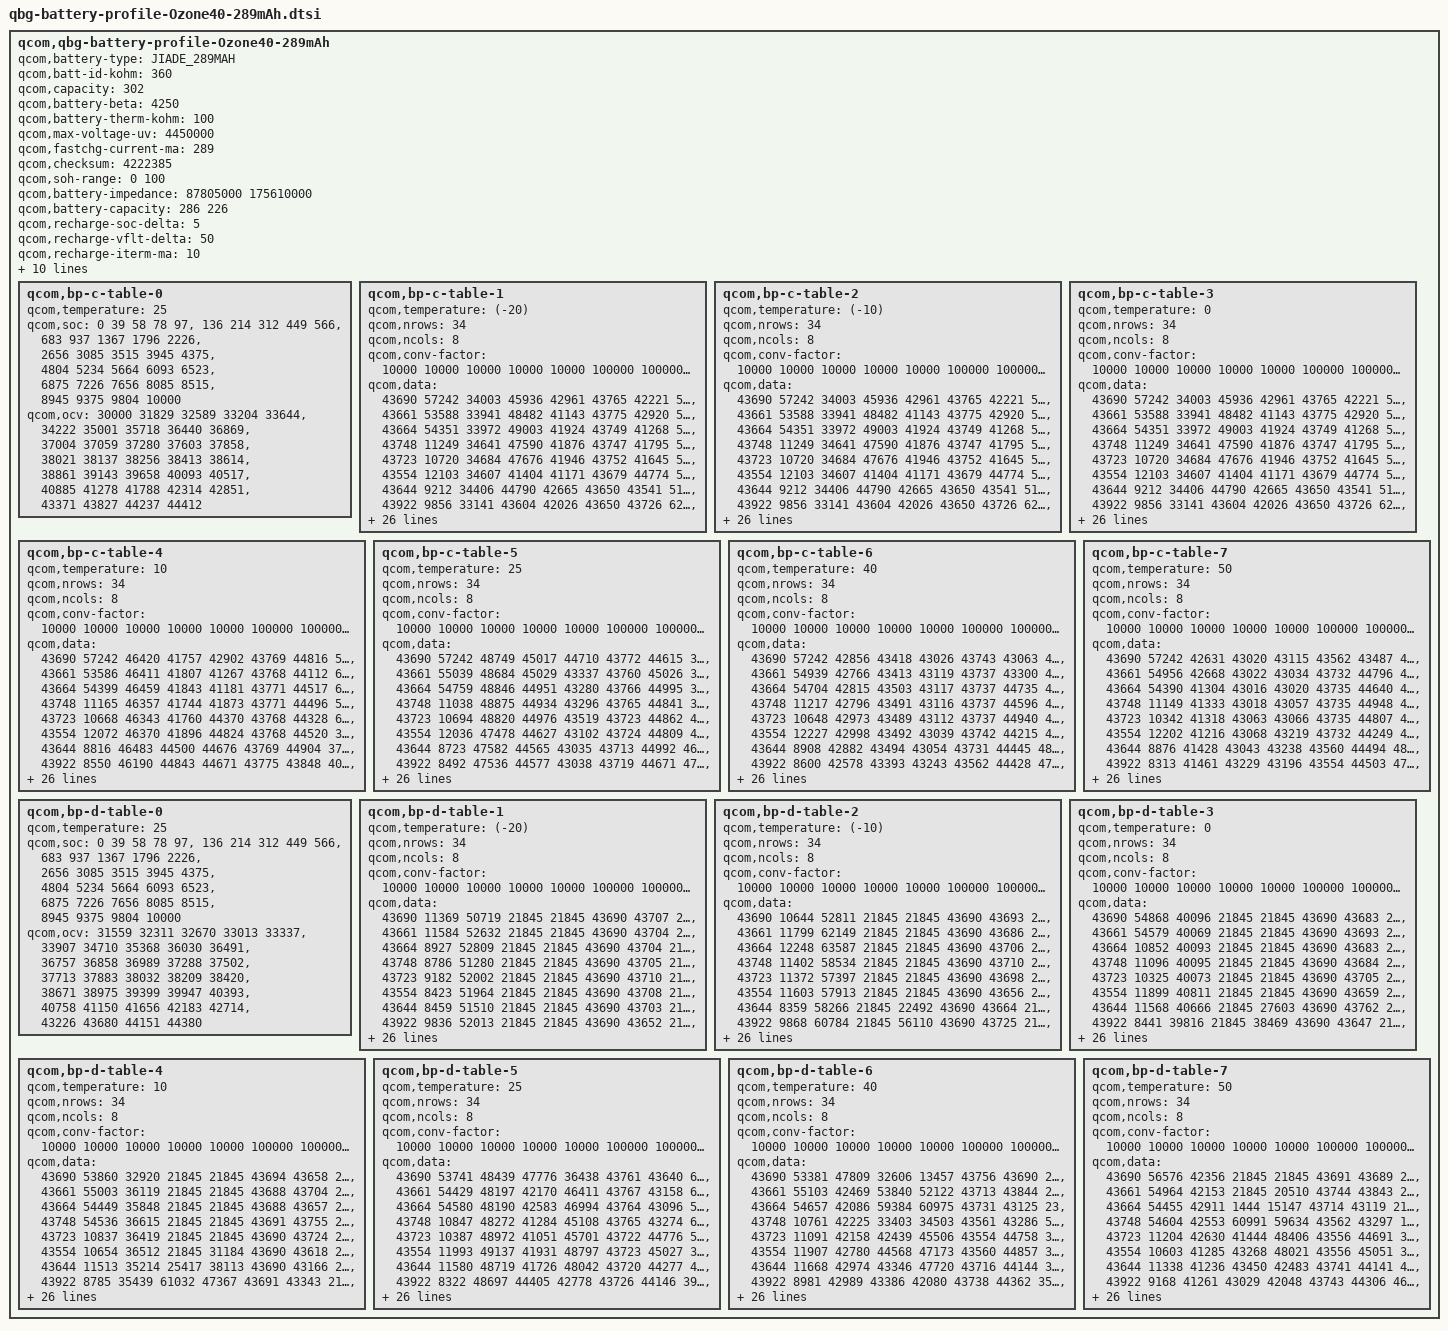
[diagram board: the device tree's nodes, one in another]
qcom,qbg-battery-profile-Ozone40-289mAh {
	qcom,battery-type = "JIADE_289MAH";
	qcom,batt-id-kohm = <360>;
	qcom,capacity = <302>;
	qcom,battery-beta = <4250>;
	qcom,battery-therm-kohm = <100>;
	qcom,max-voltage-uv = <4450000>;
	qcom,fastchg-current-ma = <289>;
	qcom,checksum = <4222385>; /*@5, 0.005V, 4% */
	qcom,soh-range = <0 100>;
	/* Nominal_Impedance in 10nohm @ SOC 50% 25C* 0:fresh cell, 1: aged cell */
	qcom,battery-impedance = <87805000 175610000>;
	/* Nominal_Capacity in mAh. 0: fresh cell, 1:aged cell */
	qcom,battery-capacity = <286 226>;
	/* SOC delta (in percent) dropped from EOC SOC to enable recharge */
	qcom,recharge-soc-delta =<5>;
	/* vfloat delta (in mV) dropped from regular vfloat in recharge */
	qcom,recharge-vflt-delta =<50>;
	/* Termination current (in mA) in recharge */
	qcom,recharge-iterm-ma = <10>;

	qcom,jeita-fcc-ranges = <0 150 58000
				151 435 289000
				436 445 260000
				446 450 58000>;

	qcom,jeita-fv-ranges = <0 150 4300000
				151 435 4450000
				436 445 4450000
				446 450 4350000>;

	/* COOL = 15 DegC, WARM = 45 DegC */
	qcom,jeita-soft-thresholds = <0x27c1 0x128c>;
	/* COLD = 0 DegC, HOT = 45.1 DegC */
	qcom,jeita-hard-thresholds = <0x3257 0x127e>;
	/* COOL = 18 DegC, WARM = 44 DegC*/
	qcom,jeita-soft-hys-thresholds = <0x256e 0x131c>;
	qcom,step-jeita-hysteresis = <5 5>;
	qcom,jeita-soft-fcc-ua = <96000 289000>;
	qcom,jeita-soft-fv-uv = <4300000 4300000>;

	qcom,bp-c-table-0 {
		qcom,temperature = <25>;
		qcom,soc = <    0    39    58    78    97>,
			<  136   214   312   449   566>,
			<  683   937  1367  1796  2226>,
			< 2656  3085  3515  3945  4375>,
			< 4804  5234  5664  6093  6523>,
			< 6875  7226  7656  8085  8515>,
			< 8945  9375  9804 10000>;
		qcom,ocv = <30000 31829 32589 33204 33644>,
			<34222 35001 35718 36440 36869>,
			<37004 37059 37280 37603 37858>,
			<38021 38137 38256 38413 38614>,
			<38861 39143 39658 40093 40517>,
			<40885 41278 41788 42314 42851>,
			<43371 43827 44237 44412>;
	};
	qcom,bp-c-table-1 {
		qcom,temperature = <(-20)>;
		qcom,nrows = <34>;
		qcom,ncols = <8>;
		qcom,conv-factor = <10000 10000 10000 10000 10000 100000 100000 10000>;
		qcom,data = <43690 57242 34003 45936 42961 43765 42221 54386>,
			<43661 53588 33941 48482 41143 43775 42920 54227>,
			<43664 54351 33972 49003 41924 43749 41268 56556>,
			<43748 11249 34641 47590 41876 43747 41795 55361>,
			<43723 10720 34684 47676 41946 43752 41645 50477>,
			<43554 12103 34607 41404 41171 43679 44774 50052>,
			<43644  9212 34406 44790 42665 43650 43541 51988>,
			<43922  9856 33141 43604 42026 43650 43726 62584>,
			<43883  9301 33066 43565 42160 43664 43724 61736>,
			<43164 15062 33073 43733 42763 43668 43727 62334>,
			<43009 14925 33233 43534 42875 43668 43725 61973>,
			<43267 15261 33115 41943 44247 43770 43061 62463>,
			<45053 14466 33169 42923 44407 43774 44995 61753>,
			<44462 14808 32780 42859 41097 43763 44898 63117>,
			<41496 16094 32980 42239 41249 43760 44896 63183>,
			<41162 16319 32991 42058 42532 43760 44844 62985>,
			<42663 16325 32964 42488 42951 43763 44996 63004>,
			<42769 16248 33536 42242 42821 43762 45027 63083>,
			<42435 15587 33016 47805 42011 43773 45031 63377>,
			<48061 15478 33758 47640 42298 43772 44800 62626>,
			<47214 15642 33536 48049 42492 43772 44232 63251>,
			<48856 12870 33599 48107 42940 43769 44077 61841>,
			<48266 12487 33731 48026 41386 43749 44855 64845>,
			<48487 12612 33582 47698 41388 43751 43306 64920>,
			<46033 14296 33766 48103 42559 43750 43508 62069>,
			<45169 13386 33670 47897 41242 43750 43514 61986>,
			<46736  2809 33377 47337 41284 43750 43423 62038>,
			<46914  2178 33284 47110 42999 43750 43077 61509>,
			<46399  3763 33678 47200 47805 43748 43204 62492>,
			<35817  3254 33621 47471 48268 43748 43861 49713>,
			<34907   648 33263 48640 46328 43749 43798 57094>,
			<36405   187 34366 48782 34316 43748 43989  9055>,
			<36070  1705 34420 41425 34773 43600 43638  9184>,
			<36282  1542 34815 41196 35916 43721 43540 10503>;
	};
	qcom,bp-c-table-2 {
		qcom,temperature = <(-10)>;
		qcom,nrows = <34>;
		qcom,ncols = <8>;
		qcom,conv-factor = <10000 10000 10000 10000 10000 100000 100000 10000>;
		qcom,data = <43690 57242 34003 45936 42961 43765 42221 54386>,
			<43661 53588 33941 48482 41143 43775 42920 54227>,
			<43664 54351 33972 49003 41924 43749 41268 56556>,
			<43748 11249 34641 47590 41876 43747 41795 55361>,
			<43723 10720 34684 47676 41946 43752 41645 50477>,
			<43554 12103 34607 41404 41171 43679 44774 50052>,
			<43644  9212 34406 44790 42665 43650 43541 51988>,
			<43922  9856 33141 43604 42026 43650 43726 62584>,
			<43883  9301 33066 43565 42160 43664 43724 61736>,
			<43164 15062 33073 43733 42763 43668 43727 62334>,
			<43009 14925 33233 43534 42875 43668 43725 61973>,
			<43267 15261 33115 41943 44247 43770 43061 62463>,
			<45053 14466 33169 42923 44407 43774 44995 61753>,
			<44462 14808 32780 42859 41097 43763 44898 63117>,
			<41496 16094 32980 42239 41249 43760 44896 63183>,
			<41162 16319 32991 42058 42532 43760 44844 62985>,
			<42663 16325 32964 42488 42951 43763 44996 63004>,
			<42769 16248 33536 42242 42821 43762 45027 63083>,
			<42435 15587 33016 47805 42011 43773 45031 63377>,
			<48061 15478 33758 47640 42298 43772 44800 62626>,
			<47214 15642 33536 48049 42492 43772 44232 63251>,
			<48856 12870 33599 48107 42940 43769 44077 61841>,
			<48266 12487 33731 48026 41386 43749 44855 64845>,
			<48487 12612 33582 47698 41388 43751 43306 64920>,
			<46033 14296 33766 48103 42559 43750 43508 62069>,
			<45169 13386 33670 47897 41242 43750 43514 61986>,
			<46736  2809 33377 47337 41284 43750 43423 62038>,
			<46914  2178 33284 47110 42999 43750 43077 61509>,
			<46399  3763 33678 47200 47805 43748 43204 62492>,
			<35817  3254 33621 47471 48268 43748 43861 49713>,
			<34907   648 33263 48640 46328 43749 43798 57094>,
			<36405   187 34366 48782 34316 43748 43989  9055>,
			<36070  1705 34420 41425 34773 43600 43638  9184>,
			<36282  1542 34815 41196 35916 43721 43540 10503>;
	};
	qcom,bp-c-table-3 {
		qcom,temperature = <0>;
		qcom,nrows = <34>;
		qcom,ncols = <8>;
		qcom,conv-factor = <10000 10000 10000 10000 10000 100000 100000 10000>;
		qcom,data = <43690 57242 34003 45936 42961 43765 42221 54386>,
			<43661 53588 33941 48482 41143 43775 42920 54227>,
			<43664 54351 33972 49003 41924 43749 41268 56556>,
			<43748 11249 34641 47590 41876 43747 41795 55361>,
			<43723 10720 34684 47676 41946 43752 41645 50477>,
			<43554 12103 34607 41404 41171 43679 44774 50052>,
			<43644  9212 34406 44790 42665 43650 43541 51988>,
			<43922  9856 33141 43604 42026 43650 43726 62584>,
			<43883  9301 33066 43565 42160 43664 43724 61736>,
			<43164 15062 33073 43733 42763 43668 43727 62334>,
			<43009 14925 33233 43534 42875 43668 43725 61973>,
			<43267 15261 33115 41943 44247 43770 43061 62463>,
			<45053 14466 33169 42923 44407 43774 44995 61753>,
			<44462 14808 32780 42859 41097 43763 44898 63117>,
			<41496 16094 32980 42239 41249 43760 44896 63183>,
			<41162 16319 32991 42058 42532 43760 44844 62985>,
			<42663 16325 32964 42488 42951 43763 44996 63004>,
			<42769 16248 33536 42242 42821 43762 45027 63083>,
			<42435 15587 33016 47805 42011 43773 45031 63377>,
			<48061 15478 33758 47640 42298 43772 44800 62626>,
			<47214 15642 33536 48049 42492 43772 44232 63251>,
			<48856 12870 33599 48107 42940 43769 44077 61841>,
			<48266 12487 33731 48026 41386 43749 44855 64845>,
			<48487 12612 33582 47698 41388 43751 43306 64920>,
			<46033 14296 33766 48103 42559 43750 43508 62069>,
			<45169 13386 33670 47897 41242 43750 43514 61986>,
			<46736  2809 33377 47337 41284 43750 43423 62038>,
			<46914  2178 33284 47110 42999 43750 43077 61509>,
			<46399  3763 33678 47200 47805 43748 43204 62492>,
			<35817  3254 33621 47471 48268 43748 43861 49713>,
			<34907   648 33263 48640 46328 43749 43798 57094>,
			<36405   187 34366 48782 34316 43748 43989  9055>,
			<36070  1705 34420 41425 34773 43600 43638  9184>,
			<36282  1542 34815 41196 35916 43721 43540 10503>;
	};
	qcom,bp-c-table-4 {
		qcom,temperature = <10>;
		qcom,nrows = <34>;
		qcom,ncols = <8>;
		qcom,conv-factor = <10000 10000 10000 10000 10000 100000 100000 10000>;
		qcom,data = <43690 57242 46420 41757 42902 43769 44816 59027>,
			<43661 53586 46411 41807 41267 43768 44112 60758>,
			<43664 54399 46459 41843 41181 43771 44517 61284>,
			<43748 11165 46357 41744 41873 43771 44496 59660>,
			<43723 10668 46343 41760 44370 43768 44328 60196>,
			<43554 12072 46370 41896 44824 43768 44520 38672>,
			<43644  8816 46483 44500 44676 43769 44904 37432>,
			<43922  8550 46190 44843 44671 43775 43848 40711>,
			<43883  9218 46244 44810 44763 43761 43151 40588>,
			<43164 15075 46239 45032 44781 43767 43859 38934>,
			<43009 14872 46946 45005 44675 43766 43177 39100>,
			<43267 14937 46873 44429 43287 43722 44655 38916>,
			<45053 15219 47053 41672 44180 43720 44828 40847>,
			<44462 14729 46991 41579 44354 43726 44896 40784>,
			<41496 16000 46675 41882 41597 43724 44202 40141>,
			<41162 15979 46593 41729 41977 43727 44186 39992>,
			<42663 16264 46785 41121 41946 43726 44185 39969>,
			<42769 16190 46793 41186 41971 43720 44825 40174>,
			<42435 15501 46847 41178 41775 43722 44641 40175>,
			<48061 15475 46776 41195 40984 43765 43358 40057>,
			<47214 15631 45385 41013 42702 43765 44786 37598>,
			<48856 12802 45337 41429 42898 43726 44145 37732>,
			<48266 12339 45560 41012 41677 43764 44849 39368>,
			<48487 14019 45459 41027 44263 43713 44727 39681>,
			<46033 13472 45451 41461 44161 43742 43333 39805>,
			<45169 13778 45480 41438 44222 43737 44718 39784>,
			<46736  2649 45486 41240 44140 43739 43309 38985>,
			<46914  2173 45462 41333 41718 43766 43419 40455>,
			<46399  3658 45567 41302 41850 43763 43036 39962>,
			<35817  3164 45371 42514 41451 43762 43059 37827>,
			<34907   597 45403 42958 42048 43762 43202 38396>,
			<36405   124 46699 42987 45793 43763 43849 57599>,
			<36070  1599 46995 44413 48913 43571 43931 61349>,
			<36282  1936 46880 44902 48948 43775 43645 61079>;
	};
	qcom,bp-c-table-5 {
		qcom,temperature = <25>;
		qcom,nrows = <34>;
		qcom,ncols = <8>;
		qcom,conv-factor = <10000 10000 10000 10000 10000 100000 100000 10000>;
		qcom,data = <43690 57242 48749 45017 44710 43772 44615 35033>,
			<43661 55039 48684 45029 43337 43760 45026 35802>,
			<43664 54759 48846 44951 43280 43766 44995 35392>,
			<43748 11038 48875 44934 43296 43765 44841 35535>,
			<43723 10694 48820 44976 43519 43723 44862 46414>,
			<43554 12036 47478 44627 43102 43724 44809 46161>,
			<43644  8723 47582 44565 43035 43713 44992 46960>,
			<43922  8492 47536 44577 43038 43719 44671 47004>,
			<43883  9458 47230 44681 43078 43739 43391 46635>,
			<43164 15023 47110 44717 43106 43737 44573 45396>,
			<43009 14886 47154 43364 43263 43736 44784 45501>,
			<43267 14953 47327 44782 43421 43737 44632 46747>,
			<45053 15114 47236 44567 45011 43742 44740 46112>,
			<44462 14409 47275 44975 44239 43730 44647 46532>,
			<41496 14664 47995 44995 44036 43741 44857 46456>,
			<41162 15919 47885 44836 44226 43737 44905 46549>,
			<42663 15955 47918 44819 44208 43738 44807 46491>,
			<42769 16346 48116 44211 44197 43716 45055 46568>,
			<42435 15527 48007 44077 44169 43719 44600 46337>,
			<48061 15484 47708 44033 44048 43717 43326 35479>,
			<47214 15719 47731 44875 41596 43737 43050 35839>,
			<48856 12877 47671 44906 41051 43715 43515 35232>,
			<48266 12352 47836 44867 44944 43719 44650 47097>,
			<48487 13879 47853 44809 44778 43713 43379 45416>,
			<46033 13551 47764 44829 44737 43718 43506 45407>,
			<45169 13599 47761 44874 44571 43718 43423 46808>,
			<46736  2964 47772 44206 44954 43713 43076 47027>,
			<46914  2454 47771 44208 44883 43712 43064 46254>,
			<46399  4064 47766 44145 44242 43713 43083 46576>,
			<35817  3529 47820 44320 44538 43719 43426 35726>,
			<34907   961 47674 44318 41523 43716 43106 34894>,
			<36405   409 47718 44381 42165 43739 43234 33667>,
			<36070  1639 48063 44894 42950 43712 43185 35956>,
			<36282  2006 48071 44727 42063 43719 43921 35842>;
	};
	qcom,bp-c-table-6 {
		qcom,temperature = <40>;
		qcom,nrows = <34>;
		qcom,ncols = <8>;
		qcom,conv-factor = <10000 10000 10000 10000 10000 100000 100000 10000>;
		qcom,data = <43690 57242 42856 43418 43026 43743 43063 49025>,
			<43661 54939 42766 43413 43119 43737 43300 49068>,
			<43664 54704 42815 43503 43117 43737 44735 48731>,
			<43748 11217 42796 43491 43116 43737 44596 48753>,
			<43723 10648 42973 43489 43112 43737 44940 48745>,
			<43554 12227 42998 43492 43039 43742 44215 48698>,
			<43644  8908 42882 43494 43054 43731 44445 48816>,
			<43922  8600 42578 43393 43243 43562 44428 47576>,
			<43883  9388 42595 43108 43235 43552 44649 47175>,
			<43164  9491 42513 43112 43250 43579 44833 47230>,
			<43009 15088 42510 43146 43169 43582 44953 47972>,
			<43267 14881 42545 43216 43081 43579 44790 47189>,
			<45053 15347 42543 43118 44724 43576 43364 48861>,
			<44462 14396 42706 43028 44737 43577 44709 48646>,
			<41496 14628 42696 43107 44583 43578 44701 48749>,
			<41162 16106 42723 43082 44720 43559 44979 48888>,
			<42663 15968 42628 43072 43326 43565 44639 47468>,
			<42769 16381 42684 43428 43300 43560 44686 47478>,
			<42435 15534 41301 43309 43342 43562 43293 48652>,
			<48061 15474 41292 43337 44581 43732 43494 48901>,
			<47214 15740 41316 43356 44905 43735 43069 48240>,
			<48856 13242 41233 43272 44473 43565 43258 48484>,
			<48266 12375 41229 43500 44719 43561 44948 48776>,
			<48487 13930 41273 43068 43013 43567 43399 47952>,
			<46033 13505 41261 43093 43025 43566 43267 47307>,
			<45169 13640 41260 43431 43454 43566 43467 47221>,
			<46736  3033 41257 43453 43316 43561 43438 47557>,
			<46914  2527 41431 43513 44677 43563 43100 48866>,
			<46399  3885 41263 43368 44565 43733 43414 49136>,
			<35817  3381 41255 43336 45013 43732 43073 48276>,
			<34907   830 41270 44790 44174 43564 43498 48595>,
			<36405   505 41323 44986 44395 43555 43402 45230>,
			<36070  1602 41329 43491 44325 43560 43202 48467>,
			<36282  1844 41242 43036 44364 43570 43823 48620>;
	};
	qcom,bp-c-table-7 {
		qcom,temperature = <50>;
		qcom,nrows = <34>;
		qcom,ncols = <8>;
		qcom,conv-factor = <10000 10000 10000 10000 10000 100000 100000 10000>;
		qcom,data = <43690 57242 42631 43020 43115 43562 43487 47134>,
			<43661 54956 42668 43022 43034 43732 44796 47320>,
			<43664 54390 41304 43016 43020 43735 44640 47354>,
			<43748 11149 41333 43018 43057 43735 44948 47236>,
			<43723 10342 41318 43063 43066 43735 44807 47270>,
			<43554 12202 41216 43068 43219 43732 44249 47969>,
			<43644  8876 41428 43043 43238 43560 44494 48119>,
			<43922  8313 41461 43229 43196 43554 44503 47692>,
			<43883  9999 41375 43228 43853 43557 44316 47648>,
			<43164  9673 41357 43138 43842 43569 45011 47759>,
			<43009 15028 41407 43836 43874 43524 45050 42481>,
			<43267 15099 41401 43877 43046 43535 43317 47862>,
			<45053 15292 41380 43188 43411 43522 43371 48123>,
			<44462 14584 41045 43863 43475 43526 43371 48079>,
			<41496 14829 41029 43871 43266 43534 43371 48084>,
			<41162 16058 41039 43866 43511 43531 44775 48055>,
			<42663 15879 41086 43180 43104 43575 44645 47629>,
			<42769 16364 40977 43250 43027 43582 44564 47719>,
			<42435 16214 40963 43013 43447 43559 44708 47923>,
			<48061 15475 41013 43109 43391 43553 43428 47327>,
			<47214 15732 41017 43127 44568 43552 43229 47604>,
			<48856 13195 41002 43425 44949 43557 43222 48813>,
			<48266 12710 41159 43146 43476 43569 43293 48008>,
			<48487 13926 41206 43869 43869 43583 44772 42489>,
			<46033 13526 41211 43176 43234 43570 43301 42241>,
			<45169 13660 41191 43233 43042 43581 43345 47774>,
			<46736  2850 41199 43216 43081 43583 44706 47727>,
			<46914  2342 41108 43045 43473 43582 43298 48090>,
			<46399  3851 41197 43027 44706 43579 43457 47262>,
			<35817  3333 41196 43092 44594 43559 43320 47525>,
			<34907   779 41184 43405 44980 43577 43484 47458>,
			<36405   499 41203 43482 44825 43578 43315 48662>,
			<36070  1607 41204 43069 45021 43568 43083 47370>,
			<36282  1806 41828 43870 44119 43575 43779 48828>;
	};
	qcom,bp-d-table-0 {
		qcom,temperature = <25>;
		qcom,soc = <    0    39    58    78    97>,
			<  136   214   312   449   566>,
			<  683   937  1367  1796  2226>,
			< 2656  3085  3515  3945  4375>,
			< 4804  5234  5664  6093  6523>,
			< 6875  7226  7656  8085  8515>,
			< 8945  9375  9804 10000>;
		qcom,ocv = <31559 32311 32670 33013 33337>,
			<33907 34710 35368 36030 36491>,
			<36757 36858 36989 37288 37502>,
			<37713 37883 38032 38209 38420>,
			<38671 38975 39399 39947 40393>,
			<40758 41150 41656 42183 42714>,
			<43226 43680 44151 44380>;
	};
	qcom,bp-d-table-1 {
		qcom,temperature = <(-20)>;
		qcom,nrows = <34>;
		qcom,ncols = <8>;
		qcom,conv-factor = <10000 10000 10000 10000 10000 100000 100000 10000>;
		qcom,data = <43690 11369 50719 21845 21845 43690 43707 21845>,
			<43661 11584 52632 21845 21845 43690 43704 21845>,
			<43664  8927 52809 21845 21845 43690 43704 21845>,
			<43748  8786 51280 21845 21845 43690 43705 21845>,
			<43723  9182 52002 21845 21845 43690 43710 21845>,
			<43554  8423 51964 21845 21845 43690 43708 21845>,
			<43644  8459 51510 21845 21845 43690 43703 21845>,
			<43922  9836 52013 21845 21845 43690 43652 21845>,
			<43883 10110 63066 21845 15323 43690 43766 21845>,
			<43164  9422 61708 21845 49306 43690 43743 21845>,
			<43009  9331 64986 21845 58787 43690 43570 21845>,
			<43267  9485 64552 21845 39291 43690 43632 21845>,
			<45053 14907 63768 21845 34074 43690 43930 21845>,
			<44462 15341 64483 19007 32816 43691 44030 21845>,
			<41496 15193 59222  3184 34896 43691 43832 21845>,
			<41162 14397 57392 53374 45555 43691 43894 21845>,
			<42663 14746 58056 52182 48410 43691 43901 21845>,
			<42769 14695 58275 65138 48319 43691 43899 21845>,
			<42435 16065 58269 57412 48996 43691 43792 21845>,
			<48061 16294 58134 59462 48997 43688 43785 21845>,
			<47214 16146 58232 37143 48354 43688 43808 21845>,
			<48856 15572 58079 40798 48145 43688 43990 21845>,
			<48266 15662 58120 39272 48966 43688 43878 21845>,
			<48487 13231 60744 39210 48599 43688 43223 21845>,
			<46033 12312 58173 39156 45093 43688 43223 21845>,
			<45169 14218 58159 39947 35112 43689 45009 21845>,
			<46736 13807 58335 37562 34439 43694 44234 21845>,
			<46914  2655 58113 40951 34080 43694 43508 21845>,
			<46399  2257 58140 40366 32875 43692 43028 21845>,
			<35817  4023 58214 39396 33748 43664 44740 21845>,
			<34907  3563 57960 37524 33120 43659 43318 21845>,
			<36405   965 58297 59405 33390 43687 43222 21845>,
			<36070  1677 57419 63677 46460 43690 43908 21845>,
			<36282  1800 57681 62191 45367 43690 43947 21845>;
	};
	qcom,bp-d-table-2 {
		qcom,temperature = <(-10)>;
		qcom,nrows = <34>;
		qcom,ncols = <8>;
		qcom,conv-factor = <10000 10000 10000 10000 10000 100000 100000 10000>;
		qcom,data = <43690 10644 52811 21845 21845 43690 43693 21845>,
			<43661 11799 62149 21845 21845 43690 43686 21845>,
			<43664 12248 63587 21845 21845 43690 43706 21845>,
			<43748 11402 58534 21845 21845 43690 43710 21845>,
			<43723 11372 57397 21845 21845 43690 43698 21845>,
			<43554 11603 57913 21845 21845 43690 43656 21845>,
			<43644  8359 58266 21845 22492 43690 43664 21845>,
			<43922  9868 60784 21845 56110 43690 43725 21845>,
			<43883  9353 61118 21845 37458 43690 43952 21845>,
			<43164  9331 59439 21845 36001 43690 43992 21845>,
			<43009  9622 37902 17773 45316 43690 43836 21845>,
			<43267  9544 38419 11419 48042 43691 43175 21845>,
			<45053 14969 36880 63470 47622 43691 43157 21845>,
			<44462 15143 36964 58666 48127 43691 43161 21845>,
			<41496 14488 37055 38352 47836 43688 43146 21845>,
			<41162 14461 37110 39116 42478 43688 43233 22278>,
			<42663 14788 37037 33470 41993 43688 43153 16775>,
			<42769 14672 37724 35727 42153 43689 43188 30626>,
			<42435 15919 37656 45339 42821 43694 43841 31671>,
			<48061 16266 37762 48418 42860 43692 43891 27854>,
			<47214 15522 37823 48317 42993 43711 43090 27443>,
			<48856 15675 36975 48130 42231 43746 44130 27406>,
			<48266 13199 36916 48629 47570 43751 44168 26812>,
			<48487 12316 36992 45706 49116 43749 44616 27591>,
			<46033 14234 37037 45475 35433 43751 44919 26337>,
			<45169 13316 37640 45209 36428 43750 44681 26135>,
			<46736  2704 37659 45356 36416 43751 43499 26403>,
			<46914  2081 37065 36374 35819 43749 45039 30814>,
			<46399  3830 37829 34818 35200 43753 43281 30750>,
			<35817  3280 37000 35077 36360 43753 43279 31957>,
			<34907   732 37645 36463 36559 43752 43462 28856>,
			<36405   149 37093 36390 46214 43665 43439 29307>,
			<36070  1729 38624 34891 47911 43652 43230 30970>,
			<36282  1847 38829 35790 42084 43648 43141 26596>;
	};
	qcom,bp-d-table-3 {
		qcom,temperature = <0>;
		qcom,nrows = <34>;
		qcom,ncols = <8>;
		qcom,conv-factor = <10000 10000 10000 10000 10000 100000 100000 10000>;
		qcom,data = <43690 54868 40096 21845 21845 43690 43683 21845>,
			<43661 54579 40069 21845 21845 43690 43693 21845>,
			<43664 10852 40093 21845 21845 43690 43683 21845>,
			<43748 11096 40095 21845 21845 43690 43684 21845>,
			<43723 10325 40073 21845 21845 43690 43705 21845>,
			<43554 11899 40811 21845 21845 43690 43659 21845>,
			<43644 11568 40666 21845 27603 43690 43762 21845>,
			<43922  8441 39816 21845 38469 43690 43647 21845>,
			<43883 10136 34007  6204 49053 43690 43872 21845>,
			<43164  9233 34426 51730 47768 43691 43046 21845>,
			<43009  9710 34367 59642 42143 43691 43052 21845>,
			<43267  9493 33096 36094 40966 43688 43052 24633>,
			<45053 14902 33111 48968 41842 43694 43242  2527>,
			<44462 15122 33024 48883 41338 43682 43476 13080>,
			<41496 14337 33073 42311 41330 43670 44900  9965>,
			<41162 14745 32841 42136 41178 43750 45021 54438>,
			<42663 14640 33179 42953 41726 43771 44645 55305>,
			<42769 16047 33273 42506 44477 43769 44699 49935>,
			<42435 15872 32869 42499 44439 43769 44633 53090>,
			<48061 16157 32788 42849 41931 43775 44477 52818>,
			<47214 15487 33251 42146 41413 43760 44211 52897>,
			<48856 12982 33237 42033 42929 43760 44999 51473>,
			<48266 13117 33235 42391 42060 43761 44652 52984>,
			<48487 12679 32870 47827 42312 43761 44765 53039>,
			<46033 14307 33198 47830 48202 43761 43423 49567>,
			<45169 13758 32820 47608 48336 43763 43384 50376>,
			<46736  2656 32994 48287 49064 43772 44606 50456>,
			<46914  2156 33193 48895 48563 43768 43414 56015>,
			<46399  3705 33197 48690 48566 43770 43435 56179>,
			<35817  3151 32842 49058 48526 43770 43438 55661>,
			<34907   590 33218 49141 48614 43770 43428 56554>,
			<36405    49 33262 48749 47479 43748 43424 57145>,
			<36070  1573 32998 47541 42654 43746 43097 56315>,
			<36282  1842 33578 47325 41173 43757 43083 51063>;
	};
	qcom,bp-d-table-4 {
		qcom,temperature = <10>;
		qcom,nrows = <34>;
		qcom,ncols = <8>;
		qcom,conv-factor = <10000 10000 10000 10000 10000 100000 100000 10000>;
		qcom,data = <43690 53860 32920 21845 21845 43694 43658 21845>,
			<43661 55003 36119 21845 21845 43688 43704 21845>,
			<43664 54449 35848 21845 21845 43688 43657 21845>,
			<43748 54536 36615 21845 21845 43691 43755 21845>,
			<43723 10837 36419 21845 21845 43690 43724 21845>,
			<43554 10654 36512 21845 31184 43690 43618 21845>,
			<43644 11513 35214 25417 38113 43690 43166 21845>,
			<43922  8785 35439 61032 47367 43691 43343 21337>,
			<43883  9893 46456 45487 42578 43694 43464 13179>,
			<43164  9370 35515 48123 42678 43687 43467 55260>,
			<43009  9696 46554 42785 41336 43697 43447 50222>,
			<43267  9599 46399 41196 44378 43653 43473 61973>,
			<45053 14891 46565 41528 44282 43664 43383 60876>,
			<44462 15124 46096 41971 41711 43775 44669 60633>,
			<41496 14350 46139 41923 41533 43767 44857 60327>,
			<41162 14750 46262 41882 44398 43723 44218 38637>,
			<42663 14599 46969 41566 44134 43720 44247 37484>,
			<42769 16122 46865 41902 44464 43726 44099 40223>,
			<42435 16267 47044 41895 41662 43724 44170 40440>,
			<48061 15530 47077 41880 41636 43727 45002 40113>,
			<47214 15779 46677 41972 41657 43727 44628 40948>,
			<48856 13035 46704 41766 41691 43721 44756 40851>,
			<48266 13076 46630 41143 41982 43721 44756 40171>,
			<48487 12583 46810 41392 41250 43721 44665 37835>,
			<46033 14093 46820 42929 42855 43720 44583 38681>,
			<45169 13821 46817 42979 41993 43722 43334 37936>,
			<46736  2654 46785 42609 42107 43766 43413 37888>,
			<46914  2140 46656 42512 42841 43763 43116 37934>,
			<46399  4013 46693 42596 42987 43772 43016 37909>,
			<35817  3508 47031 42912 42516 43773 43082 38177>,
			<34907   950 47058 42943 42564 43763 43445 60375>,
			<36405   125 46913 42546 41232 43761 43458 60289>,
			<36070  1538 46288 41427 41503 43767 43285 38050>,
			<36282  1831 46143 41370 44353 43767 43330 37354>;
	};
	qcom,bp-d-table-5 {
		qcom,temperature = <25>;
		qcom,nrows = <34>;
		qcom,ncols = <8>;
		qcom,conv-factor = <10000 10000 10000 10000 10000 100000 100000 10000>;
		qcom,data = <43690 53741 48439 47776 36438 43761 43640 61626>,
			<43661 54429 48197 42170 46411 43767 43158 64014>,
			<43664 54580 48190 42583 46994 43764 43096 57621>,
			<43748 10847 48272 41284 45108 43765 43274 60499>,
			<43723 10387 48972 41051 45701 43722 44776 59433>,
			<43554 11993 49137 41931 48797 43723 45027 37344>,
			<43644 11580 48719 41726 48042 43720 44277 40906>,
			<43922  8322 48697 44405 42778 43726 44146 39477>,
			<43883  9748 48795 44439 44415 43727 44231 33668>,
			<43164  9249 48826 44187 44206 43720 43383 36861>,
			<43009  9535 47365 44169 44456 43724 43091 36661>,
			<43267  9552 47580 45051 44758 43725 44724 35713>,
			<45053 15063 47545 44737 43460 43712 44767 46271>,
			<44462 15106 47124 44647 44571 43716 44672 46517>,
			<41496 14548 47138 44646 44970 43736 44965 46097>,
			<41162 14843 47334 44941 44420 43730 44035 35349>,
			<42663 14673 47276 44979 41661 43729 44910 35834>,
			<42769 15930 47979 44625 44330 43734 44787 46417>,
			<42435 16363 48080 44970 44270 43728 44705 46298>,
			<48061 15550 48025 44615 45045 43741 43378 46990>,
			<47214 15781 48041 44626 44646 43743 43353 46839>,
			<48856 12949 47715 44972 44548 43738 44713 46782>,
			<48266 13133 47629 44871 44134 43742 45051 46511>,
			<48487 13985 47834 44430 41293 43729 44633 36834>,
			<46033 14179 47813 44051 41468 43736 43429 36554>,
			<45169 13724 47808 44080 41794 43717 43237 34836>,
			<46736  2580 47820 44035 41673 43716 43142 35786>,
			<46914  2066 47675 44152 44152 43715 43238 35471>,
			<46399  3693 47668 44474 45015 43714 43080 46471>,
			<35817  3184 47632 44049 44962 43724 43407 46118>,
			<34907   624 48040 44180 44967 43724 43418 46331>,
			<36405    10 48111 44904 44628 43712 43511 46245>,
			<36070  1757 48080 45028 44665 43737 43292 46869>,
			<36282  2038 47905 44983 44651 43740 43377 46909>;
	};
	qcom,bp-d-table-6 {
		qcom,temperature = <40>;
		qcom,nrows = <34>;
		qcom,ncols = <8>;
		qcom,conv-factor = <10000 10000 10000 10000 10000 100000 100000 10000>;
		qcom,data = <43690 53381 47809 32606 13457 43756 43690 21845>,
			<43661 55103 42469 53840 52122 43713 43844 21002>,
			<43664 54657 42086 59384 60975 43731 43125    23>,
			<43748 10761 42225 33403 34503 43561 43286 50131>,
			<43723 11091 42158 42439 45506 43554 44758 37228>,
			<43554 11907 42780 44568 47173 43560 44857 35909>,
			<43644 11668 42974 43346 47720 43716 44144 35120>,
			<43922  8981 42989 43386 42080 43738 44362 35723>,
			<43883  9871 42913 43294 44915 43730 41609 48499>,
			<43164  9406 42570 43314 43451 43733 44393 48746>,
			<43009  9676 42612 43313 43374 43733 43299 49118>,
			<43267  9548 42618 43425 43079 43561 44715 47429>,
			<45053 15086 42521 43162 43158 43577 44664 47235>,
			<44462 15309 42552 43224 43400 43576 44721 47508>,
			<41496 14574 42706 43254 43291 43583 44725 47422>,
			<41162 14732 42696 43042 44961 43570 44696 48727>,
			<42663 16042 42734 43108 44183 43572 43380 48370>,
			<42769 15903 42633 43132 44165 43572 43299 48272>,
			<42435 16321 42669 43013 44936 43571 43408 48718>,
			<48061 15510 41285 43057 43329 43582 43405 47407>,
			<47214 15773 41288 43105 43424 43556 44778 47126>,
			<48856 13006 41325 43121 43124 43555 44969 47167>,
			<48266 12443 41229 43481 44085 43559 44647 48204>,
			<48487 14007 41226 44721 41688 43580 43130 45878>,
			<46033 14192 41268 44551 44144 43578 43062 45609>,
			<45169 13799 41270 44558 44998 43564 43016 48573>,
			<46736  2674 41277 44755 44589 43735 43030 48290>,
			<46914  2174 41276 44582 43457 43740 43282 49069>,
			<46399  3656 41219 44746 43024 43742 44547 48795>,
			<35817  3163 41241 43318 43038 43743 43327 47576>,
			<34907   577 41312 43500 43051 43731 43387 47170>,
			<36405    26 41294 43123 43066 43733 43286 47142>,
			<36070  1753 42666 43241 43103 43554 43394 47351>,
			<36282  2018 42662 43859 43503 43559 43039 47351>;
	};
	qcom,bp-d-table-7 {
		qcom,temperature = <50>;
		qcom,nrows = <34>;
		qcom,ncols = <8>;
		qcom,conv-factor = <10000 10000 10000 10000 10000 100000 100000 10000>;
		qcom,data = <43690 56576 42356 21845 21845 43691 43689 21845>,
			<43661 54964 42153 21845 20510 43744 43843 21845>,
			<43664 54455 42911  1444 15147 43714 43119 21845>,
			<43748 54604 42553 60991 59634 43562 43297 12987>,
			<43723 11204 42630 41444 48406 43556 44691 39826>,
			<43554 10603 41285 43268 48021 43556 45051 34950>,
			<43644 11338 41236 43450 42483 43741 44141 46576>,
			<43922  9168 41261 43029 42048 43743 44306 46328>,
			<43883  8574 41419 43029 44074 43733 41678 48903>,
			<43164 10013 41451 43013 43072 43565 41550 47988>,
			<43009  9608 41362 43098 43121 43565 44963 47282>,
			<43267  9501 41345 43256 43046 43557 43285 48036>,
			<45053 15034 41392 43825 43852 43524 44962 42280>,
			<44462 15259 41388 43800 43113 43533 43266 47817>,
			<41496 14525 41054 43876 43396 43524 44719 47735>,
			<41162 14418 41032 43883 43293 43525 43264 48111>,
			<42663 14680 41060 43869 44952 43545 43466 47194>,
			<42769 15982 40978 43193 44813 43551 43431 47557>,
			<42435 16351 40972 43864 44770 43547 43077 47946>,
			<48061 15588 41011 43247 43426 43521 43344 47729>,
			<47214 15855 41018 43843 43043 43528 43369 42322>,
			<48856 13019 41169 43898 43228 43575 44717 42344>,
			<48266 12512 41152 43037 44193 43533 44681 48866>,
			<48487 13965 41163 43486 44270 43529 43026 49101>,
			<46033 14154 41207 43314 44938 43582 43012 48835>,
			<45169 13820 41202 43293 43389 43558 43518 47612>,
			<46736  2635 41214 43363 43444 43565 43333 47137>,
			<46914  2163 41204 43442 43121 43562 43512 47921>,
			<46399  3660 41203 43102 43234 43563 44698 47680>,
			<35817  3167 41165 43106 43854 43561 44964 47857>,
			<34907   576 41205 43207 43887 43552 45007 42261>,
			<36405     4 41164 43169 43892 43583 44939 42436>,
			<36070  1753 41000 43777 43167 43532 44698 42460>,
			<36282  2018 41019 43819 43208 43523 43290 42244>;
	};
};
